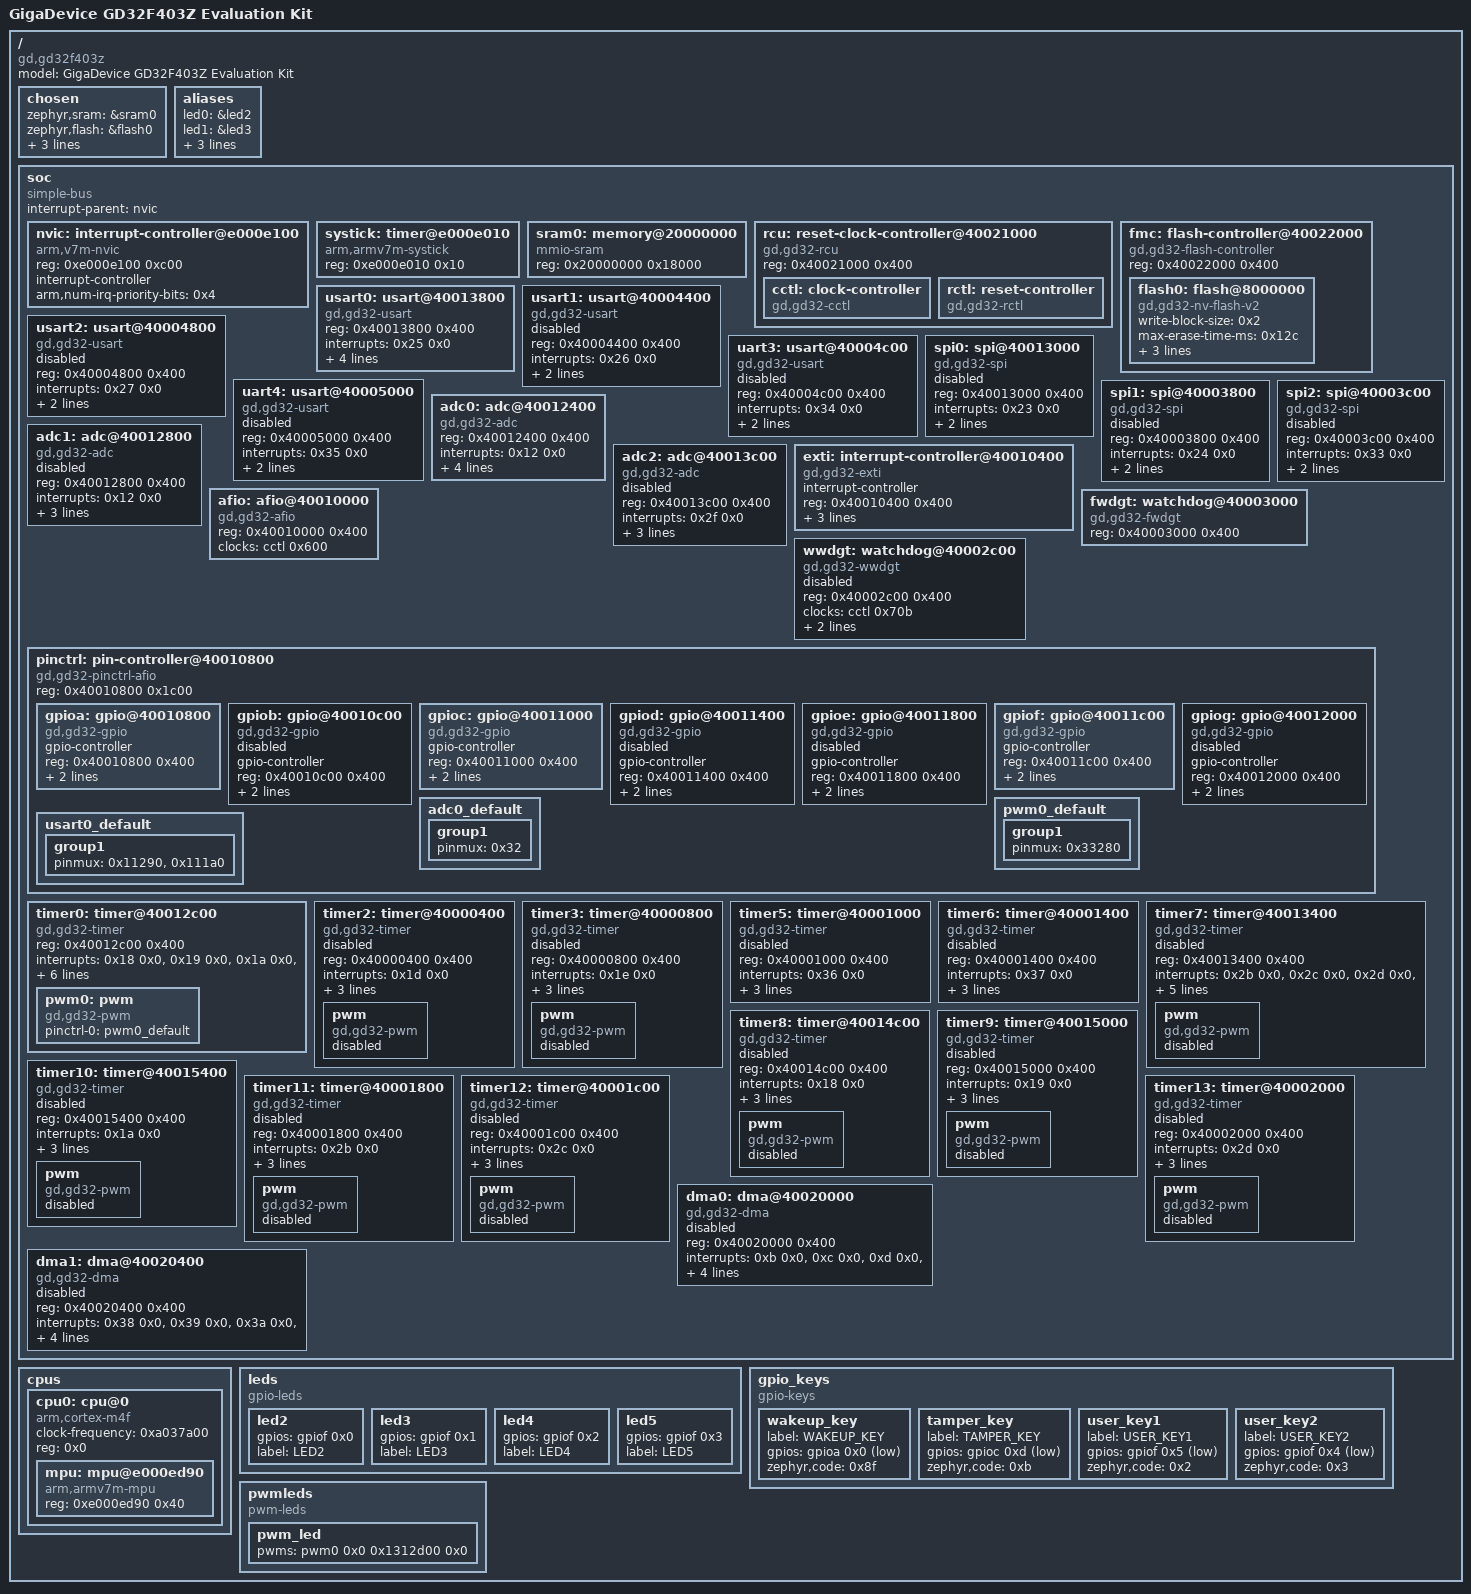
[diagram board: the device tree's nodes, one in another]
/dts-v1/;

/* node '/' defined in zephyr/dts/common/skeleton.dtsi:9 */
/ {
	#address-cells = < 0x1 >;                      /* in zephyr/dts/common/skeleton.dtsi:10 */
	#size-cells = < 0x1 >;                         /* in zephyr/dts/common/skeleton.dtsi:11 */
	model = "GigaDevice GD32F403Z Evaluation Kit"; /* in zephyr/boards/gd/gd32f403z_eval/gd32f403z_eval.dts:13 */
	compatible = "gd,gd32f403z";                   /* in zephyr/boards/gd/gd32f403z_eval/gd32f403z_eval.dts:14 */

	/* node '/chosen' defined in zephyr/dts/common/skeleton.dtsi:13 */
	chosen {
		zephyr,sram = &sram0;           /* in zephyr/boards/gd/gd32f403z_eval/gd32f403z_eval.dts:17 */
		zephyr,flash = &flash0;         /* in zephyr/boards/gd/gd32f403z_eval/gd32f403z_eval.dts:18 */
		zephyr,console = &usart0;       /* in zephyr/boards/gd/gd32f403z_eval/gd32f403z_eval.dts:19 */
		zephyr,shell-uart = &usart0;    /* in zephyr/boards/gd/gd32f403z_eval/gd32f403z_eval.dts:20 */
		zephyr,flash-controller = &fmc; /* in zephyr/boards/gd/gd32f403z_eval/gd32f403z_eval.dts:21 */
	};

	/* node '/aliases' defined in zephyr/dts/common/skeleton.dtsi:15 */
	aliases {
		led0 = &led2;        /* in zephyr/boards/gd/gd32f403z_eval/gd32f403z_eval.dts:86 */
		led1 = &led3;        /* in zephyr/boards/gd/gd32f403z_eval/gd32f403z_eval.dts:87 */
		sw0 = &user_key1;    /* in zephyr/boards/gd/gd32f403z_eval/gd32f403z_eval.dts:88 */
		pwm-led0 = &pwm_led; /* in zephyr/boards/gd/gd32f403z_eval/gd32f403z_eval.dts:89 */
		watchdog0 = &fwdgt;  /* in zephyr/boards/gd/gd32f403z_eval/gd32f403z_eval.dts:90 */
	};

	/* node '/soc' defined in zephyr/dts/arm/armv7-m.dtsi:6 */
	soc {
		#address-cells = < 0x1 >;     /* in zephyr/dts/arm/armv7-m.dtsi:7 */
		#size-cells = < 0x1 >;        /* in zephyr/dts/arm/armv7-m.dtsi:8 */
		compatible = "simple-bus";    /* in zephyr/dts/arm/armv7-m.dtsi:9 */
		interrupt-parent = < &nvic >; /* in zephyr/dts/arm/armv7-m.dtsi:10 */
		ranges;                       /* in zephyr/dts/arm/armv7-m.dtsi:11 */

		/* node '/soc/interrupt-controller@e000e100' defined in zephyr/dts/arm/armv7-m.dtsi:13 */
		nvic: interrupt-controller@e000e100 {
			#address-cells = < 0x1 >;            /* in zephyr/dts/arm/armv7-m.dtsi:14 */
			compatible = "arm,v7m-nvic";         /* in zephyr/dts/arm/armv7-m.dtsi:15 */
			reg = < 0xe000e100 0xc00 >;          /* in zephyr/dts/arm/armv7-m.dtsi:16 */
			interrupt-controller;                /* in zephyr/dts/arm/armv7-m.dtsi:17 */
			#interrupt-cells = < 0x2 >;          /* in zephyr/dts/arm/armv7-m.dtsi:18 */
			arm,num-irq-priority-bits = < 0x4 >; /* in zephyr/dts/arm/gd/gd32f403/gd32f403.dtsi:519 */
			phandle = < 0x1 >;                   /* in zephyr/dts/arm/armv7-m.dtsi:10 */
		};

		/* node '/soc/timer@e000e010' defined in zephyr/dts/arm/armv7-m.dtsi:21 */
		systick: timer@e000e010 {
			compatible = "arm,armv7m-systick"; /* in zephyr/dts/arm/armv7-m.dtsi:22 */
			reg = < 0xe000e010 0x10 >;         /* in zephyr/dts/arm/armv7-m.dtsi:23 */
		};

		/* node '/soc/memory@20000000' defined in zephyr/dts/arm/gd/gd32f403/gd32f403.dtsi:36 */
		sram0: memory@20000000 {
			compatible = "mmio-sram";     /* in zephyr/dts/arm/gd/gd32f403/gd32f403.dtsi:37 */
			reg = < 0x20000000 0x18000 >; /* in zephyr/dts/arm/gd/gd32f403/gd32f403zet6.dtsi:15 */
		};

		/* node '/soc/reset-clock-controller@40021000' defined in zephyr/dts/arm/gd/gd32f403/gd32f403.dtsi:40 */
		rcu: reset-clock-controller@40021000 {
			compatible = "gd,gd32-rcu"; /* in zephyr/dts/arm/gd/gd32f403/gd32f403.dtsi:41 */
			reg = < 0x40021000 0x400 >; /* in zephyr/dts/arm/gd/gd32f403/gd32f403.dtsi:42 */
			status = "okay";            /* in zephyr/dts/arm/gd/gd32f403/gd32f403.dtsi:43 */

			/* node '/soc/reset-clock-controller@40021000/clock-controller' defined in zephyr/dts/arm/gd/gd32f403/gd32f403.dtsi:45 */
			cctl: clock-controller {
				compatible = "gd,gd32-cctl"; /* in zephyr/dts/arm/gd/gd32f403/gd32f403.dtsi:46 */
				#clock-cells = < 0x1 >;      /* in zephyr/dts/arm/gd/gd32f403/gd32f403.dtsi:47 */
				status = "okay";             /* in zephyr/dts/arm/gd/gd32f403/gd32f403.dtsi:48 */
				phandle = < 0x2 >;           /* in zephyr/dts/arm/gd/gd32f403/gd32f403.dtsi:77 */
			};

			/* node '/soc/reset-clock-controller@40021000/reset-controller' defined in zephyr/dts/arm/gd/gd32f403/gd32f403.dtsi:51 */
			rctl: reset-controller {
				compatible = "gd,gd32-rctl"; /* in zephyr/dts/arm/gd/gd32f403/gd32f403.dtsi:52 */
				#reset-cells = < 0x1 >;      /* in zephyr/dts/arm/gd/gd32f403/gd32f403.dtsi:53 */
				status = "okay";             /* in zephyr/dts/arm/gd/gd32f403/gd32f403.dtsi:54 */
				phandle = < 0x3 >;           /* in zephyr/dts/arm/gd/gd32f403/gd32f403.dtsi:78 */
			};
		};

		/* node '/soc/flash-controller@40022000' defined in zephyr/dts/arm/gd/gd32f403/gd32f403.dtsi:58 */
		fmc: flash-controller@40022000 {
			compatible = "gd,gd32-flash-controller"; /* in zephyr/dts/arm/gd/gd32f403/gd32f403.dtsi:59 */
			reg = < 0x40022000 0x400 >;              /* in zephyr/dts/arm/gd/gd32f403/gd32f403.dtsi:60 */
			#address-cells = < 0x1 >;                /* in zephyr/dts/arm/gd/gd32f403/gd32f403.dtsi:61 */
			#size-cells = < 0x1 >;                   /* in zephyr/dts/arm/gd/gd32f403/gd32f403.dtsi:62 */

			/* node '/soc/flash-controller@40022000/flash@8000000' defined in zephyr/dts/arm/gd/gd32f403/gd32f403.dtsi:64 */
			flash0: flash@8000000 {
				compatible = "gd,gd32-nv-flash-v2",
				             "soc-nv-flash";        /* in zephyr/dts/arm/gd/gd32f403/gd32f403.dtsi:65 */
				write-block-size = < 0x2 >;         /* in zephyr/dts/arm/gd/gd32f403/gd32f403.dtsi:66 */
				max-erase-time-ms = < 0x12c >;      /* in zephyr/dts/arm/gd/gd32f403/gd32f403.dtsi:67 */
				bank0-page-size = < 0x800 >;        /* in zephyr/dts/arm/gd/gd32f403/gd32f403.dtsi:68 */
				bank1-page-size = < 0x1000 >;       /* in zephyr/dts/arm/gd/gd32f403/gd32f403.dtsi:69 */
				reg = < 0x8000000 0x80000 >;        /* in zephyr/dts/arm/gd/gd32f403/gd32f403zet6.dtsi:11 */
			};
		};

		/* node '/soc/usart@40013800' defined in zephyr/dts/arm/gd/gd32f403/gd32f403.dtsi:73 */
		usart0: usart@40013800 {
			compatible = "gd,gd32-usart";    /* in zephyr/dts/arm/gd/gd32f403/gd32f403.dtsi:74 */
			reg = < 0x40013800 0x400 >;      /* in zephyr/dts/arm/gd/gd32f403/gd32f403.dtsi:75 */
			interrupts = < 0x25 0x0 >;       /* in zephyr/dts/arm/gd/gd32f403/gd32f403.dtsi:76 */
			clocks = < &cctl 0x60e >;        /* in zephyr/dts/arm/gd/gd32f403/gd32f403.dtsi:77 */
			resets = < &rctl 0x30e >;        /* in zephyr/dts/arm/gd/gd32f403/gd32f403.dtsi:78 */
			status = "okay";                 /* in zephyr/boards/gd/gd32f403z_eval/gd32f403z_eval.dts:113 */
			current-speed = < 0x1c200 >;     /* in zephyr/boards/gd/gd32f403z_eval/gd32f403z_eval.dts:114 */
			pinctrl-0 = < &usart0_default >; /* in zephyr/boards/gd/gd32f403z_eval/gd32f403z_eval.dts:115 */
			pinctrl-names = "default";       /* in zephyr/boards/gd/gd32f403z_eval/gd32f403z_eval.dts:116 */
		};

		/* node '/soc/usart@40004400' defined in zephyr/dts/arm/gd/gd32f403/gd32f403.dtsi:82 */
		usart1: usart@40004400 {
			compatible = "gd,gd32-usart"; /* in zephyr/dts/arm/gd/gd32f403/gd32f403.dtsi:83 */
			reg = < 0x40004400 0x400 >;   /* in zephyr/dts/arm/gd/gd32f403/gd32f403.dtsi:84 */
			interrupts = < 0x26 0x0 >;    /* in zephyr/dts/arm/gd/gd32f403/gd32f403.dtsi:85 */
			clocks = < &cctl 0x711 >;     /* in zephyr/dts/arm/gd/gd32f403/gd32f403.dtsi:86 */
			resets = < &rctl 0x411 >;     /* in zephyr/dts/arm/gd/gd32f403/gd32f403.dtsi:87 */
			status = "disabled";          /* in zephyr/dts/arm/gd/gd32f403/gd32f403.dtsi:88 */
		};

		/* node '/soc/usart@40004800' defined in zephyr/dts/arm/gd/gd32f403/gd32f403.dtsi:91 */
		usart2: usart@40004800 {
			compatible = "gd,gd32-usart"; /* in zephyr/dts/arm/gd/gd32f403/gd32f403.dtsi:92 */
			reg = < 0x40004800 0x400 >;   /* in zephyr/dts/arm/gd/gd32f403/gd32f403.dtsi:93 */
			interrupts = < 0x27 0x0 >;    /* in zephyr/dts/arm/gd/gd32f403/gd32f403.dtsi:94 */
			clocks = < &cctl 0x712 >;     /* in zephyr/dts/arm/gd/gd32f403/gd32f403.dtsi:95 */
			resets = < &rctl 0x412 >;     /* in zephyr/dts/arm/gd/gd32f403/gd32f403.dtsi:96 */
			status = "disabled";          /* in zephyr/dts/arm/gd/gd32f403/gd32f403.dtsi:97 */
		};

		/* node '/soc/usart@40004c00' defined in zephyr/dts/arm/gd/gd32f403/gd32f403.dtsi:100 */
		uart3: usart@40004c00 {
			compatible = "gd,gd32-usart"; /* in zephyr/dts/arm/gd/gd32f403/gd32f403.dtsi:101 */
			reg = < 0x40004c00 0x400 >;   /* in zephyr/dts/arm/gd/gd32f403/gd32f403.dtsi:102 */
			interrupts = < 0x34 0x0 >;    /* in zephyr/dts/arm/gd/gd32f403/gd32f403.dtsi:103 */
			clocks = < &cctl 0x713 >;     /* in zephyr/dts/arm/gd/gd32f403/gd32f403.dtsi:104 */
			resets = < &rctl 0x413 >;     /* in zephyr/dts/arm/gd/gd32f403/gd32f403.dtsi:105 */
			status = "disabled";          /* in zephyr/dts/arm/gd/gd32f403/gd32f403.dtsi:106 */
		};

		/* node '/soc/usart@40005000' defined in zephyr/dts/arm/gd/gd32f403/gd32f403.dtsi:109 */
		uart4: usart@40005000 {
			compatible = "gd,gd32-usart"; /* in zephyr/dts/arm/gd/gd32f403/gd32f403.dtsi:110 */
			reg = < 0x40005000 0x400 >;   /* in zephyr/dts/arm/gd/gd32f403/gd32f403.dtsi:111 */
			interrupts = < 0x35 0x0 >;    /* in zephyr/dts/arm/gd/gd32f403/gd32f403.dtsi:112 */
			clocks = < &cctl 0x714 >;     /* in zephyr/dts/arm/gd/gd32f403/gd32f403.dtsi:113 */
			resets = < &rctl 0x414 >;     /* in zephyr/dts/arm/gd/gd32f403/gd32f403.dtsi:114 */
			status = "disabled";          /* in zephyr/dts/arm/gd/gd32f403/gd32f403.dtsi:115 */
		};

		/* node '/soc/spi@40013000' defined in zephyr/dts/arm/gd/gd32f403/gd32f403.dtsi:118 */
		spi0: spi@40013000 {
			compatible = "gd,gd32-spi"; /* in zephyr/dts/arm/gd/gd32f403/gd32f403.dtsi:119 */
			reg = < 0x40013000 0x400 >; /* in zephyr/dts/arm/gd/gd32f403/gd32f403.dtsi:120 */
			interrupts = < 0x23 0x0 >;  /* in zephyr/dts/arm/gd/gd32f403/gd32f403.dtsi:121 */
			clocks = < &cctl 0x60c >;   /* in zephyr/dts/arm/gd/gd32f403/gd32f403.dtsi:122 */
			resets = < &rctl 0x30c >;   /* in zephyr/dts/arm/gd/gd32f403/gd32f403.dtsi:123 */
			status = "disabled";        /* in zephyr/dts/arm/gd/gd32f403/gd32f403.dtsi:124 */
			#address-cells = < 0x1 >;   /* in zephyr/dts/arm/gd/gd32f403/gd32f403.dtsi:125 */
			#size-cells = < 0x0 >;      /* in zephyr/dts/arm/gd/gd32f403/gd32f403.dtsi:126 */
		};

		/* node '/soc/spi@40003800' defined in zephyr/dts/arm/gd/gd32f403/gd32f403.dtsi:129 */
		spi1: spi@40003800 {
			compatible = "gd,gd32-spi"; /* in zephyr/dts/arm/gd/gd32f403/gd32f403.dtsi:130 */
			reg = < 0x40003800 0x400 >; /* in zephyr/dts/arm/gd/gd32f403/gd32f403.dtsi:131 */
			interrupts = < 0x24 0x0 >;  /* in zephyr/dts/arm/gd/gd32f403/gd32f403.dtsi:132 */
			clocks = < &cctl 0x70e >;   /* in zephyr/dts/arm/gd/gd32f403/gd32f403.dtsi:133 */
			resets = < &rctl 0x40e >;   /* in zephyr/dts/arm/gd/gd32f403/gd32f403.dtsi:134 */
			status = "disabled";        /* in zephyr/dts/arm/gd/gd32f403/gd32f403.dtsi:135 */
			#address-cells = < 0x1 >;   /* in zephyr/dts/arm/gd/gd32f403/gd32f403.dtsi:136 */
			#size-cells = < 0x0 >;      /* in zephyr/dts/arm/gd/gd32f403/gd32f403.dtsi:137 */
		};

		/* node '/soc/spi@40003c00' defined in zephyr/dts/arm/gd/gd32f403/gd32f403.dtsi:140 */
		spi2: spi@40003c00 {
			compatible = "gd,gd32-spi"; /* in zephyr/dts/arm/gd/gd32f403/gd32f403.dtsi:141 */
			reg = < 0x40003c00 0x400 >; /* in zephyr/dts/arm/gd/gd32f403/gd32f403.dtsi:142 */
			interrupts = < 0x33 0x0 >;  /* in zephyr/dts/arm/gd/gd32f403/gd32f403.dtsi:143 */
			clocks = < &cctl 0x70f >;   /* in zephyr/dts/arm/gd/gd32f403/gd32f403.dtsi:144 */
			resets = < &rctl 0x40f >;   /* in zephyr/dts/arm/gd/gd32f403/gd32f403.dtsi:145 */
			status = "disabled";        /* in zephyr/dts/arm/gd/gd32f403/gd32f403.dtsi:146 */
			#address-cells = < 0x1 >;   /* in zephyr/dts/arm/gd/gd32f403/gd32f403.dtsi:147 */
			#size-cells = < 0x0 >;      /* in zephyr/dts/arm/gd/gd32f403/gd32f403.dtsi:148 */
		};

		/* node '/soc/adc@40012400' defined in zephyr/dts/arm/gd/gd32f403/gd32f403.dtsi:151 */
		adc0: adc@40012400 {
			compatible = "gd,gd32-adc";    /* in zephyr/dts/arm/gd/gd32f403/gd32f403.dtsi:152 */
			reg = < 0x40012400 0x400 >;    /* in zephyr/dts/arm/gd/gd32f403/gd32f403.dtsi:153 */
			interrupts = < 0x12 0x0 >;     /* in zephyr/dts/arm/gd/gd32f403/gd32f403.dtsi:154 */
			clocks = < &cctl 0x609 >;      /* in zephyr/dts/arm/gd/gd32f403/gd32f403.dtsi:155 */
			resets = < &rctl 0x309 >;      /* in zephyr/dts/arm/gd/gd32f403/gd32f403.dtsi:156 */
			channels = < 0x10 >;           /* in zephyr/dts/arm/gd/gd32f403/gd32f403.dtsi:157 */
			#io-channel-cells = < 0x1 >;   /* in zephyr/dts/arm/gd/gd32f403/gd32f403.dtsi:159 */
			status = "okay";               /* in zephyr/boards/gd/gd32f403z_eval/gd32f403z_eval.dts:107 */
			pinctrl-0 = < &adc0_default >; /* in zephyr/boards/gd/gd32f403z_eval/gd32f403z_eval.dts:108 */
			pinctrl-names = "default";     /* in zephyr/boards/gd/gd32f403z_eval/gd32f403z_eval.dts:109 */
		};

		/* node '/soc/adc@40012800' defined in zephyr/dts/arm/gd/gd32f403/gd32f403.dtsi:162 */
		adc1: adc@40012800 {
			compatible = "gd,gd32-adc";  /* in zephyr/dts/arm/gd/gd32f403/gd32f403.dtsi:163 */
			reg = < 0x40012800 0x400 >;  /* in zephyr/dts/arm/gd/gd32f403/gd32f403.dtsi:164 */
			interrupts = < 0x12 0x0 >;   /* in zephyr/dts/arm/gd/gd32f403/gd32f403.dtsi:165 */
			clocks = < &cctl 0x60a >;    /* in zephyr/dts/arm/gd/gd32f403/gd32f403.dtsi:166 */
			resets = < &rctl 0x30a >;    /* in zephyr/dts/arm/gd/gd32f403/gd32f403.dtsi:167 */
			channels = < 0x10 >;         /* in zephyr/dts/arm/gd/gd32f403/gd32f403.dtsi:168 */
			status = "disabled";         /* in zephyr/dts/arm/gd/gd32f403/gd32f403.dtsi:169 */
			#io-channel-cells = < 0x1 >; /* in zephyr/dts/arm/gd/gd32f403/gd32f403.dtsi:170 */
		};

		/* node '/soc/adc@40013c00' defined in zephyr/dts/arm/gd/gd32f403/gd32f403.dtsi:173 */
		adc2: adc@40013c00 {
			compatible = "gd,gd32-adc";  /* in zephyr/dts/arm/gd/gd32f403/gd32f403.dtsi:174 */
			reg = < 0x40013c00 0x400 >;  /* in zephyr/dts/arm/gd/gd32f403/gd32f403.dtsi:175 */
			interrupts = < 0x2f 0x0 >;   /* in zephyr/dts/arm/gd/gd32f403/gd32f403.dtsi:176 */
			clocks = < &cctl 0x60f >;    /* in zephyr/dts/arm/gd/gd32f403/gd32f403.dtsi:177 */
			resets = < &rctl 0x30f >;    /* in zephyr/dts/arm/gd/gd32f403/gd32f403.dtsi:178 */
			channels = < 0x10 >;         /* in zephyr/dts/arm/gd/gd32f403/gd32f403.dtsi:179 */
			status = "disabled";         /* in zephyr/dts/arm/gd/gd32f403/gd32f403.dtsi:180 */
			#io-channel-cells = < 0x1 >; /* in zephyr/dts/arm/gd/gd32f403/gd32f403.dtsi:181 */
		};

		/* node '/soc/interrupt-controller@40010400' defined in zephyr/dts/arm/gd/gd32f403/gd32f403.dtsi:184 */
		exti: interrupt-controller@40010400 {
			compatible = "gd,gd32-exti";   /* in zephyr/dts/arm/gd/gd32f403/gd32f403.dtsi:185 */
			interrupt-controller;          /* in zephyr/dts/arm/gd/gd32f403/gd32f403.dtsi:186 */
			#interrupt-cells = < 0x1 >;    /* in zephyr/dts/arm/gd/gd32f403/gd32f403.dtsi:187 */
			reg = < 0x40010400 0x400 >;    /* in zephyr/dts/arm/gd/gd32f403/gd32f403.dtsi:188 */
			num-lines = < 0x13 >;          /* in zephyr/dts/arm/gd/gd32f403/gd32f403.dtsi:189 */
			interrupts = < 0x6 0x0 >,
			             < 0x7 0x0 >,
			             < 0x8 0x0 >,
			             < 0x9 0x0 >,
			             < 0xa 0x0 >,
			             < 0x17 0x0 >,
			             < 0x28 0x0 >;     /* in zephyr/dts/arm/gd/gd32f403/gd32f403.dtsi:190 */
			interrupt-names = "line0",
			                  "line1",
			                  "line2",
			                  "line3",
			                  "line4",
			                  "line5-9",
			                  "line10-15"; /* in zephyr/dts/arm/gd/gd32f403/gd32f403.dtsi:192 */
			status = "okay";               /* in zephyr/dts/arm/gd/gd32f403/gd32f403.dtsi:195 */
		};

		/* node '/soc/afio@40010000' defined in zephyr/dts/arm/gd/gd32f403/gd32f403.dtsi:198 */
		afio: afio@40010000 {
			compatible = "gd,gd32-afio"; /* in zephyr/dts/arm/gd/gd32f403/gd32f403.dtsi:199 */
			reg = < 0x40010000 0x400 >;  /* in zephyr/dts/arm/gd/gd32f403/gd32f403.dtsi:200 */
			clocks = < &cctl 0x600 >;    /* in zephyr/dts/arm/gd/gd32f403/gd32f403.dtsi:201 */
			status = "okay";             /* in zephyr/dts/arm/gd/gd32f403/gd32f403.dtsi:202 */
		};

		/* node '/soc/watchdog@40003000' defined in zephyr/dts/arm/gd/gd32f403/gd32f403.dtsi:205 */
		fwdgt: watchdog@40003000 {
			compatible = "gd,gd32-fwdgt"; /* in zephyr/dts/arm/gd/gd32f403/gd32f403.dtsi:206 */
			reg = < 0x40003000 0x400 >;   /* in zephyr/dts/arm/gd/gd32f403/gd32f403.dtsi:207 */
			status = "okay";              /* in zephyr/boards/gd/gd32f403z_eval/gd32f403z_eval.dts:131 */
		};

		/* node '/soc/watchdog@40002c00' defined in zephyr/dts/arm/gd/gd32f403/gd32f403.dtsi:211 */
		wwdgt: watchdog@40002c00 {
			compatible = "gd,gd32-wwdgt"; /* in zephyr/dts/arm/gd/gd32f403/gd32f403.dtsi:212 */
			reg = < 0x40002c00 0x400 >;   /* in zephyr/dts/arm/gd/gd32f403/gd32f403.dtsi:213 */
			clocks = < &cctl 0x70b >;     /* in zephyr/dts/arm/gd/gd32f403/gd32f403.dtsi:214 */
			resets = < &rctl 0x40b >;     /* in zephyr/dts/arm/gd/gd32f403/gd32f403.dtsi:215 */
			interrupts = < 0x0 0x0 >;     /* in zephyr/dts/arm/gd/gd32f403/gd32f403.dtsi:216 */
			status = "disabled";          /* in zephyr/dts/arm/gd/gd32f403/gd32f403.dtsi:217 */
		};

		/* node '/soc/pin-controller@40010800' defined in zephyr/dts/arm/gd/gd32f403/gd32f403.dtsi:220 */
		pinctrl: pin-controller@40010800 {
			compatible = "gd,gd32-pinctrl-afio"; /* in zephyr/dts/arm/gd/gd32f403/gd32f403.dtsi:221 */
			reg = < 0x40010800 0x1c00 >;         /* in zephyr/dts/arm/gd/gd32f403/gd32f403.dtsi:222 */
			#address-cells = < 0x1 >;            /* in zephyr/dts/arm/gd/gd32f403/gd32f403.dtsi:223 */
			#size-cells = < 0x1 >;               /* in zephyr/dts/arm/gd/gd32f403/gd32f403.dtsi:224 */
			status = "okay";                     /* in zephyr/dts/arm/gd/gd32f403/gd32f403.dtsi:225 */

			/* node '/soc/pin-controller@40010800/gpio@40010800' defined in zephyr/dts/arm/gd/gd32f403/gd32f403.dtsi:227 */
			gpioa: gpio@40010800 {
				compatible = "gd,gd32-gpio"; /* in zephyr/dts/arm/gd/gd32f403/gd32f403.dtsi:228 */
				gpio-controller;             /* in zephyr/dts/arm/gd/gd32f403/gd32f403.dtsi:229 */
				#gpio-cells = < 0x2 >;       /* in zephyr/dts/arm/gd/gd32f403/gd32f403.dtsi:230 */
				reg = < 0x40010800 0x400 >;  /* in zephyr/dts/arm/gd/gd32f403/gd32f403.dtsi:231 */
				clocks = < &cctl 0x602 >;    /* in zephyr/dts/arm/gd/gd32f403/gd32f403.dtsi:232 */
				resets = < &rctl 0x302 >;    /* in zephyr/dts/arm/gd/gd32f403/gd32f403.dtsi:233 */
				status = "okay";             /* in zephyr/boards/gd/gd32f403z_eval/gd32f403z_eval.dts:95 */
				phandle = < 0x8 >;           /* in zephyr/boards/gd/gd32f403z_eval/gd32f403z_eval.dts:53 */
			};

			/* node '/soc/pin-controller@40010800/gpio@40010c00' defined in zephyr/dts/arm/gd/gd32f403/gd32f403.dtsi:237 */
			gpiob: gpio@40010c00 {
				compatible = "gd,gd32-gpio"; /* in zephyr/dts/arm/gd/gd32f403/gd32f403.dtsi:238 */
				gpio-controller;             /* in zephyr/dts/arm/gd/gd32f403/gd32f403.dtsi:239 */
				#gpio-cells = < 0x2 >;       /* in zephyr/dts/arm/gd/gd32f403/gd32f403.dtsi:240 */
				reg = < 0x40010c00 0x400 >;  /* in zephyr/dts/arm/gd/gd32f403/gd32f403.dtsi:241 */
				clocks = < &cctl 0x603 >;    /* in zephyr/dts/arm/gd/gd32f403/gd32f403.dtsi:242 */
				resets = < &rctl 0x303 >;    /* in zephyr/dts/arm/gd/gd32f403/gd32f403.dtsi:243 */
				status = "disabled";         /* in zephyr/dts/arm/gd/gd32f403/gd32f403.dtsi:244 */
			};

			/* node '/soc/pin-controller@40010800/gpio@40011000' defined in zephyr/dts/arm/gd/gd32f403/gd32f403.dtsi:247 */
			gpioc: gpio@40011000 {
				compatible = "gd,gd32-gpio"; /* in zephyr/dts/arm/gd/gd32f403/gd32f403.dtsi:248 */
				gpio-controller;             /* in zephyr/dts/arm/gd/gd32f403/gd32f403.dtsi:249 */
				#gpio-cells = < 0x2 >;       /* in zephyr/dts/arm/gd/gd32f403/gd32f403.dtsi:250 */
				reg = < 0x40011000 0x400 >;  /* in zephyr/dts/arm/gd/gd32f403/gd32f403.dtsi:251 */
				clocks = < &cctl 0x604 >;    /* in zephyr/dts/arm/gd/gd32f403/gd32f403.dtsi:252 */
				resets = < &rctl 0x304 >;    /* in zephyr/dts/arm/gd/gd32f403/gd32f403.dtsi:253 */
				status = "okay";             /* in zephyr/boards/gd/gd32f403z_eval/gd32f403z_eval.dts:99 */
				phandle = < 0x9 >;           /* in zephyr/boards/gd/gd32f403z_eval/gd32f403z_eval.dts:59 */
			};

			/* node '/soc/pin-controller@40010800/gpio@40011400' defined in zephyr/dts/arm/gd/gd32f403/gd32f403.dtsi:257 */
			gpiod: gpio@40011400 {
				compatible = "gd,gd32-gpio"; /* in zephyr/dts/arm/gd/gd32f403/gd32f403.dtsi:258 */
				gpio-controller;             /* in zephyr/dts/arm/gd/gd32f403/gd32f403.dtsi:259 */
				#gpio-cells = < 0x2 >;       /* in zephyr/dts/arm/gd/gd32f403/gd32f403.dtsi:260 */
				reg = < 0x40011400 0x400 >;  /* in zephyr/dts/arm/gd/gd32f403/gd32f403.dtsi:261 */
				clocks = < &cctl 0x605 >;    /* in zephyr/dts/arm/gd/gd32f403/gd32f403.dtsi:262 */
				resets = < &rctl 0x305 >;    /* in zephyr/dts/arm/gd/gd32f403/gd32f403.dtsi:263 */
				status = "disabled";         /* in zephyr/dts/arm/gd/gd32f403/gd32f403.dtsi:264 */
			};

			/* node '/soc/pin-controller@40010800/gpio@40011800' defined in zephyr/dts/arm/gd/gd32f403/gd32f403.dtsi:267 */
			gpioe: gpio@40011800 {
				compatible = "gd,gd32-gpio"; /* in zephyr/dts/arm/gd/gd32f403/gd32f403.dtsi:268 */
				gpio-controller;             /* in zephyr/dts/arm/gd/gd32f403/gd32f403.dtsi:269 */
				#gpio-cells = < 0x2 >;       /* in zephyr/dts/arm/gd/gd32f403/gd32f403.dtsi:270 */
				reg = < 0x40011800 0x400 >;  /* in zephyr/dts/arm/gd/gd32f403/gd32f403.dtsi:271 */
				clocks = < &cctl 0x606 >;    /* in zephyr/dts/arm/gd/gd32f403/gd32f403.dtsi:272 */
				resets = < &rctl 0x306 >;    /* in zephyr/dts/arm/gd/gd32f403/gd32f403.dtsi:273 */
				status = "disabled";         /* in zephyr/dts/arm/gd/gd32f403/gd32f403.dtsi:274 */
			};

			/* node '/soc/pin-controller@40010800/gpio@40011c00' defined in zephyr/dts/arm/gd/gd32f403/gd32f403.dtsi:277 */
			gpiof: gpio@40011c00 {
				compatible = "gd,gd32-gpio"; /* in zephyr/dts/arm/gd/gd32f403/gd32f403.dtsi:278 */
				gpio-controller;             /* in zephyr/dts/arm/gd/gd32f403/gd32f403.dtsi:279 */
				#gpio-cells = < 0x2 >;       /* in zephyr/dts/arm/gd/gd32f403/gd32f403.dtsi:280 */
				reg = < 0x40011c00 0x400 >;  /* in zephyr/dts/arm/gd/gd32f403/gd32f403.dtsi:281 */
				clocks = < &cctl 0x607 >;    /* in zephyr/dts/arm/gd/gd32f403/gd32f403.dtsi:282 */
				resets = < &rctl 0x307 >;    /* in zephyr/dts/arm/gd/gd32f403/gd32f403.dtsi:283 */
				status = "okay";             /* in zephyr/boards/gd/gd32f403z_eval/gd32f403z_eval.dts:103 */
				phandle = < 0x7 >;           /* in zephyr/boards/gd/gd32f403z_eval/gd32f403z_eval.dts:28 */
			};

			/* node '/soc/pin-controller@40010800/gpio@40012000' defined in zephyr/dts/arm/gd/gd32f403/gd32f403.dtsi:287 */
			gpiog: gpio@40012000 {
				compatible = "gd,gd32-gpio"; /* in zephyr/dts/arm/gd/gd32f403/gd32f403.dtsi:288 */
				gpio-controller;             /* in zephyr/dts/arm/gd/gd32f403/gd32f403.dtsi:289 */
				#gpio-cells = < 0x2 >;       /* in zephyr/dts/arm/gd/gd32f403/gd32f403.dtsi:290 */
				reg = < 0x40012000 0x400 >;  /* in zephyr/dts/arm/gd/gd32f403/gd32f403.dtsi:291 */
				clocks = < &cctl 0x608 >;    /* in zephyr/dts/arm/gd/gd32f403/gd32f403.dtsi:292 */
				resets = < &rctl 0x308 >;    /* in zephyr/dts/arm/gd/gd32f403/gd32f403.dtsi:293 */
				status = "disabled";         /* in zephyr/dts/arm/gd/gd32f403/gd32f403.dtsi:294 */
			};

			/* node '/soc/pin-controller@40010800/usart0_default' defined in zephyr/boards/gd/gd32f403z_eval/gd32f403z_eval-pinctrl.dtsi:9 */
			usart0_default: usart0_default {
				phandle = < 0x4 >; /* in zephyr/boards/gd/gd32f403z_eval/gd32f403z_eval.dts:115 */

				/* node '/soc/pin-controller@40010800/usart0_default/group1' defined in zephyr/boards/gd/gd32f403z_eval/gd32f403z_eval-pinctrl.dtsi:10 */
				group1 {
					pinmux = < 0x11290 >,
					         < 0x111a0 >; /* in zephyr/boards/gd/gd32f403z_eval/gd32f403z_eval-pinctrl.dtsi:11 */
				};
			};

			/* node '/soc/pin-controller@40010800/adc0_default' defined in zephyr/boards/gd/gd32f403z_eval/gd32f403z_eval-pinctrl.dtsi:15 */
			adc0_default: adc0_default {
				phandle = < 0x5 >; /* in zephyr/boards/gd/gd32f403z_eval/gd32f403z_eval.dts:108 */

				/* node '/soc/pin-controller@40010800/adc0_default/group1' defined in zephyr/boards/gd/gd32f403z_eval/gd32f403z_eval-pinctrl.dtsi:16 */
				group1 {
					pinmux = < 0x32 >; /* in zephyr/boards/gd/gd32f403z_eval/gd32f403z_eval-pinctrl.dtsi:17 */
				};
			};

			/* node '/soc/pin-controller@40010800/pwm0_default' defined in zephyr/boards/gd/gd32f403z_eval/gd32f403z_eval-pinctrl.dtsi:21 */
			pwm0_default: pwm0_default {
				phandle = < 0x6 >; /* in zephyr/boards/gd/gd32f403z_eval/gd32f403z_eval.dts:125 */

				/* node '/soc/pin-controller@40010800/pwm0_default/group1' defined in zephyr/boards/gd/gd32f403z_eval/gd32f403z_eval-pinctrl.dtsi:22 */
				group1 {
					pinmux = < 0x33280 >; /* in zephyr/boards/gd/gd32f403z_eval/gd32f403z_eval-pinctrl.dtsi:23 */
				};
			};
		};

		/* node '/soc/timer@40012c00' defined in zephyr/dts/arm/gd/gd32f403/gd32f403.dtsi:298 */
		timer0: timer@40012c00 {
			compatible = "gd,gd32-timer"; /* in zephyr/dts/arm/gd/gd32f403/gd32f403.dtsi:299 */
			reg = < 0x40012c00 0x400 >;   /* in zephyr/dts/arm/gd/gd32f403/gd32f403.dtsi:300 */
			interrupts = < 0x18 0x0 >,
			             < 0x19 0x0 >,
			             < 0x1a 0x0 >,
			             < 0x1b 0x0 >;    /* in zephyr/dts/arm/gd/gd32f403/gd32f403.dtsi:301 */
			interrupt-names = "brk",
			                  "up",
			                  "trgcom",
			                  "cc";       /* in zephyr/dts/arm/gd/gd32f403/gd32f403.dtsi:302 */
			clocks = < &cctl 0x60b >;     /* in zephyr/dts/arm/gd/gd32f403/gd32f403.dtsi:303 */
			resets = < &rctl 0x30b >;     /* in zephyr/dts/arm/gd/gd32f403/gd32f403.dtsi:304 */
			is-advanced;                  /* in zephyr/dts/arm/gd/gd32f403/gd32f403.dtsi:305 */
			channels = < 0x4 >;           /* in zephyr/dts/arm/gd/gd32f403/gd32f403.dtsi:306 */
			status = "okay";              /* in zephyr/boards/gd/gd32f403z_eval/gd32f403z_eval.dts:120 */
			prescaler = < 0x100 >;        /* in zephyr/boards/gd/gd32f403z_eval/gd32f403z_eval.dts:121 */

			/* node '/soc/timer@40012c00/pwm' defined in zephyr/dts/arm/gd/gd32f403/gd32f403.dtsi:309 */
			pwm0: pwm {
				compatible = "gd,gd32-pwm";    /* in zephyr/dts/arm/gd/gd32f403/gd32f403.dtsi:310 */
				#pwm-cells = < 0x3 >;          /* in zephyr/dts/arm/gd/gd32f403/gd32f403.dtsi:312 */
				status = "okay";               /* in zephyr/boards/gd/gd32f403z_eval/gd32f403z_eval.dts:124 */
				pinctrl-0 = < &pwm0_default >; /* in zephyr/boards/gd/gd32f403z_eval/gd32f403z_eval.dts:125 */
				pinctrl-names = "default";     /* in zephyr/boards/gd/gd32f403z_eval/gd32f403z_eval.dts:126 */
				phandle = < 0xa >;             /* in zephyr/boards/gd/gd32f403z_eval/gd32f403z_eval.dts:81 */
			};
		};

		/* node '/soc/timer@40000400' defined in zephyr/dts/arm/gd/gd32f403/gd32f403.dtsi:316 */
		timer2: timer@40000400 {
			compatible = "gd,gd32-timer"; /* in zephyr/dts/arm/gd/gd32f403/gd32f403.dtsi:317 */
			reg = < 0x40000400 0x400 >;   /* in zephyr/dts/arm/gd/gd32f403/gd32f403.dtsi:318 */
			interrupts = < 0x1d 0x0 >;    /* in zephyr/dts/arm/gd/gd32f403/gd32f403.dtsi:319 */
			interrupt-names = "global";   /* in zephyr/dts/arm/gd/gd32f403/gd32f403.dtsi:320 */
			clocks = < &cctl 0x701 >;     /* in zephyr/dts/arm/gd/gd32f403/gd32f403.dtsi:321 */
			resets = < &rctl 0x401 >;     /* in zephyr/dts/arm/gd/gd32f403/gd32f403.dtsi:322 */
			channels = < 0x4 >;           /* in zephyr/dts/arm/gd/gd32f403/gd32f403.dtsi:323 */
			status = "disabled";          /* in zephyr/dts/arm/gd/gd32f403/gd32f403.dtsi:324 */

			/* node '/soc/timer@40000400/pwm' defined in zephyr/dts/arm/gd/gd32f403/gd32f403.dtsi:326 */
			pwm {
				compatible = "gd,gd32-pwm"; /* in zephyr/dts/arm/gd/gd32f403/gd32f403.dtsi:327 */
				status = "disabled";        /* in zephyr/dts/arm/gd/gd32f403/gd32f403.dtsi:328 */
				#pwm-cells = < 0x3 >;       /* in zephyr/dts/arm/gd/gd32f403/gd32f403.dtsi:329 */
			};
		};

		/* node '/soc/timer@40000800' defined in zephyr/dts/arm/gd/gd32f403/gd32f403.dtsi:333 */
		timer3: timer@40000800 {
			compatible = "gd,gd32-timer"; /* in zephyr/dts/arm/gd/gd32f403/gd32f403.dtsi:334 */
			reg = < 0x40000800 0x400 >;   /* in zephyr/dts/arm/gd/gd32f403/gd32f403.dtsi:335 */
			interrupts = < 0x1e 0x0 >;    /* in zephyr/dts/arm/gd/gd32f403/gd32f403.dtsi:336 */
			interrupt-names = "global";   /* in zephyr/dts/arm/gd/gd32f403/gd32f403.dtsi:337 */
			clocks = < &cctl 0x702 >;     /* in zephyr/dts/arm/gd/gd32f403/gd32f403.dtsi:338 */
			resets = < &rctl 0x402 >;     /* in zephyr/dts/arm/gd/gd32f403/gd32f403.dtsi:339 */
			channels = < 0x4 >;           /* in zephyr/dts/arm/gd/gd32f403/gd32f403.dtsi:340 */
			status = "disabled";          /* in zephyr/dts/arm/gd/gd32f403/gd32f403.dtsi:341 */

			/* node '/soc/timer@40000800/pwm' defined in zephyr/dts/arm/gd/gd32f403/gd32f403.dtsi:343 */
			pwm {
				compatible = "gd,gd32-pwm"; /* in zephyr/dts/arm/gd/gd32f403/gd32f403.dtsi:344 */
				status = "disabled";        /* in zephyr/dts/arm/gd/gd32f403/gd32f403.dtsi:345 */
				#pwm-cells = < 0x3 >;       /* in zephyr/dts/arm/gd/gd32f403/gd32f403.dtsi:346 */
			};
		};

		/* node '/soc/timer@40001000' defined in zephyr/dts/arm/gd/gd32f403/gd32f403.dtsi:350 */
		timer5: timer@40001000 {
			compatible = "gd,gd32-timer"; /* in zephyr/dts/arm/gd/gd32f403/gd32f403.dtsi:351 */
			reg = < 0x40001000 0x400 >;   /* in zephyr/dts/arm/gd/gd32f403/gd32f403.dtsi:352 */
			interrupts = < 0x36 0x0 >;    /* in zephyr/dts/arm/gd/gd32f403/gd32f403.dtsi:353 */
			interrupt-names = "global";   /* in zephyr/dts/arm/gd/gd32f403/gd32f403.dtsi:354 */
			clocks = < &cctl 0x704 >;     /* in zephyr/dts/arm/gd/gd32f403/gd32f403.dtsi:355 */
			resets = < &rctl 0x404 >;     /* in zephyr/dts/arm/gd/gd32f403/gd32f403.dtsi:356 */
			channels = < 0x0 >;           /* in zephyr/dts/arm/gd/gd32f403/gd32f403.dtsi:357 */
			status = "disabled";          /* in zephyr/dts/arm/gd/gd32f403/gd32f403.dtsi:358 */
		};

		/* node '/soc/timer@40001400' defined in zephyr/dts/arm/gd/gd32f403/gd32f403.dtsi:361 */
		timer6: timer@40001400 {
			compatible = "gd,gd32-timer"; /* in zephyr/dts/arm/gd/gd32f403/gd32f403.dtsi:362 */
			reg = < 0x40001400 0x400 >;   /* in zephyr/dts/arm/gd/gd32f403/gd32f403.dtsi:363 */
			interrupts = < 0x37 0x0 >;    /* in zephyr/dts/arm/gd/gd32f403/gd32f403.dtsi:364 */
			interrupt-names = "global";   /* in zephyr/dts/arm/gd/gd32f403/gd32f403.dtsi:365 */
			clocks = < &cctl 0x705 >;     /* in zephyr/dts/arm/gd/gd32f403/gd32f403.dtsi:366 */
			resets = < &rctl 0x405 >;     /* in zephyr/dts/arm/gd/gd32f403/gd32f403.dtsi:367 */
			channels = < 0x0 >;           /* in zephyr/dts/arm/gd/gd32f403/gd32f403.dtsi:368 */
			status = "disabled";          /* in zephyr/dts/arm/gd/gd32f403/gd32f403.dtsi:369 */
		};

		/* node '/soc/timer@40013400' defined in zephyr/dts/arm/gd/gd32f403/gd32f403.dtsi:372 */
		timer7: timer@40013400 {
			compatible = "gd,gd32-timer"; /* in zephyr/dts/arm/gd/gd32f403/gd32f403.dtsi:373 */
			reg = < 0x40013400 0x400 >;   /* in zephyr/dts/arm/gd/gd32f403/gd32f403.dtsi:374 */
			interrupts = < 0x2b 0x0 >,
			             < 0x2c 0x0 >,
			             < 0x2d 0x0 >,
			             < 0x2e 0x0 >;    /* in zephyr/dts/arm/gd/gd32f403/gd32f403.dtsi:375 */
			interrupt-names = "brk",
			                  "up",
			                  "trgcom",
			                  "cc";       /* in zephyr/dts/arm/gd/gd32f403/gd32f403.dtsi:376 */
			clocks = < &cctl 0x60d >;     /* in zephyr/dts/arm/gd/gd32f403/gd32f403.dtsi:377 */
			resets = < &rctl 0x30d >;     /* in zephyr/dts/arm/gd/gd32f403/gd32f403.dtsi:378 */
			is-advanced;                  /* in zephyr/dts/arm/gd/gd32f403/gd32f403.dtsi:379 */
			channels = < 0x4 >;           /* in zephyr/dts/arm/gd/gd32f403/gd32f403.dtsi:380 */
			status = "disabled";          /* in zephyr/dts/arm/gd/gd32f403/gd32f403.dtsi:381 */

			/* node '/soc/timer@40013400/pwm' defined in zephyr/dts/arm/gd/gd32f403/gd32f403.dtsi:383 */
			pwm {
				compatible = "gd,gd32-pwm"; /* in zephyr/dts/arm/gd/gd32f403/gd32f403.dtsi:384 */
				status = "disabled";        /* in zephyr/dts/arm/gd/gd32f403/gd32f403.dtsi:385 */
				#pwm-cells = < 0x3 >;       /* in zephyr/dts/arm/gd/gd32f403/gd32f403.dtsi:386 */
			};
		};

		/* node '/soc/timer@40014c00' defined in zephyr/dts/arm/gd/gd32f403/gd32f403.dtsi:390 */
		timer8: timer@40014c00 {
			compatible = "gd,gd32-timer"; /* in zephyr/dts/arm/gd/gd32f403/gd32f403.dtsi:391 */
			reg = < 0x40014c00 0x400 >;   /* in zephyr/dts/arm/gd/gd32f403/gd32f403.dtsi:392 */
			interrupts = < 0x18 0x0 >;    /* in zephyr/dts/arm/gd/gd32f403/gd32f403.dtsi:393 */
			interrupt-names = "global";   /* in zephyr/dts/arm/gd/gd32f403/gd32f403.dtsi:394 */
			clocks = < &cctl 0x613 >;     /* in zephyr/dts/arm/gd/gd32f403/gd32f403.dtsi:395 */
			resets = < &rctl 0x313 >;     /* in zephyr/dts/arm/gd/gd32f403/gd32f403.dtsi:396 */
			channels = < 0x2 >;           /* in zephyr/dts/arm/gd/gd32f403/gd32f403.dtsi:397 */
			status = "disabled";          /* in zephyr/dts/arm/gd/gd32f403/gd32f403.dtsi:398 */

			/* node '/soc/timer@40014c00/pwm' defined in zephyr/dts/arm/gd/gd32f403/gd32f403.dtsi:400 */
			pwm {
				compatible = "gd,gd32-pwm"; /* in zephyr/dts/arm/gd/gd32f403/gd32f403.dtsi:401 */
				status = "disabled";        /* in zephyr/dts/arm/gd/gd32f403/gd32f403.dtsi:402 */
				#pwm-cells = < 0x3 >;       /* in zephyr/dts/arm/gd/gd32f403/gd32f403.dtsi:403 */
			};
		};

		/* node '/soc/timer@40015000' defined in zephyr/dts/arm/gd/gd32f403/gd32f403.dtsi:407 */
		timer9: timer@40015000 {
			compatible = "gd,gd32-timer"; /* in zephyr/dts/arm/gd/gd32f403/gd32f403.dtsi:408 */
			reg = < 0x40015000 0x400 >;   /* in zephyr/dts/arm/gd/gd32f403/gd32f403.dtsi:409 */
			interrupts = < 0x19 0x0 >;    /* in zephyr/dts/arm/gd/gd32f403/gd32f403.dtsi:410 */
			interrupt-names = "global";   /* in zephyr/dts/arm/gd/gd32f403/gd32f403.dtsi:411 */
			clocks = < &cctl 0x614 >;     /* in zephyr/dts/arm/gd/gd32f403/gd32f403.dtsi:412 */
			resets = < &rctl 0x314 >;     /* in zephyr/dts/arm/gd/gd32f403/gd32f403.dtsi:413 */
			channels = < 0x1 >;           /* in zephyr/dts/arm/gd/gd32f403/gd32f403.dtsi:414 */
			status = "disabled";          /* in zephyr/dts/arm/gd/gd32f403/gd32f403.dtsi:415 */

			/* node '/soc/timer@40015000/pwm' defined in zephyr/dts/arm/gd/gd32f403/gd32f403.dtsi:417 */
			pwm {
				compatible = "gd,gd32-pwm"; /* in zephyr/dts/arm/gd/gd32f403/gd32f403.dtsi:418 */
				status = "disabled";        /* in zephyr/dts/arm/gd/gd32f403/gd32f403.dtsi:419 */
				#pwm-cells = < 0x3 >;       /* in zephyr/dts/arm/gd/gd32f403/gd32f403.dtsi:420 */
			};
		};

		/* node '/soc/timer@40015400' defined in zephyr/dts/arm/gd/gd32f403/gd32f403.dtsi:424 */
		timer10: timer@40015400 {
			compatible = "gd,gd32-timer"; /* in zephyr/dts/arm/gd/gd32f403/gd32f403.dtsi:425 */
			reg = < 0x40015400 0x400 >;   /* in zephyr/dts/arm/gd/gd32f403/gd32f403.dtsi:426 */
			interrupts = < 0x1a 0x0 >;    /* in zephyr/dts/arm/gd/gd32f403/gd32f403.dtsi:427 */
			interrupt-names = "global";   /* in zephyr/dts/arm/gd/gd32f403/gd32f403.dtsi:428 */
			clocks = < &cctl 0x615 >;     /* in zephyr/dts/arm/gd/gd32f403/gd32f403.dtsi:429 */
			resets = < &rctl 0x315 >;     /* in zephyr/dts/arm/gd/gd32f403/gd32f403.dtsi:430 */
			channels = < 0x1 >;           /* in zephyr/dts/arm/gd/gd32f403/gd32f403.dtsi:431 */
			status = "disabled";          /* in zephyr/dts/arm/gd/gd32f403/gd32f403.dtsi:432 */

			/* node '/soc/timer@40015400/pwm' defined in zephyr/dts/arm/gd/gd32f403/gd32f403.dtsi:434 */
			pwm {
				compatible = "gd,gd32-pwm"; /* in zephyr/dts/arm/gd/gd32f403/gd32f403.dtsi:435 */
				status = "disabled";        /* in zephyr/dts/arm/gd/gd32f403/gd32f403.dtsi:436 */
				#pwm-cells = < 0x3 >;       /* in zephyr/dts/arm/gd/gd32f403/gd32f403.dtsi:437 */
			};
		};

		/* node '/soc/timer@40001800' defined in zephyr/dts/arm/gd/gd32f403/gd32f403.dtsi:441 */
		timer11: timer@40001800 {
			compatible = "gd,gd32-timer"; /* in zephyr/dts/arm/gd/gd32f403/gd32f403.dtsi:442 */
			reg = < 0x40001800 0x400 >;   /* in zephyr/dts/arm/gd/gd32f403/gd32f403.dtsi:443 */
			interrupts = < 0x2b 0x0 >;    /* in zephyr/dts/arm/gd/gd32f403/gd32f403.dtsi:444 */
			interrupt-names = "global";   /* in zephyr/dts/arm/gd/gd32f403/gd32f403.dtsi:445 */
			clocks = < &cctl 0x706 >;     /* in zephyr/dts/arm/gd/gd32f403/gd32f403.dtsi:446 */
			resets = < &rctl 0x406 >;     /* in zephyr/dts/arm/gd/gd32f403/gd32f403.dtsi:447 */
			channels = < 0x2 >;           /* in zephyr/dts/arm/gd/gd32f403/gd32f403.dtsi:448 */
			status = "disabled";          /* in zephyr/dts/arm/gd/gd32f403/gd32f403.dtsi:449 */

			/* node '/soc/timer@40001800/pwm' defined in zephyr/dts/arm/gd/gd32f403/gd32f403.dtsi:451 */
			pwm {
				compatible = "gd,gd32-pwm"; /* in zephyr/dts/arm/gd/gd32f403/gd32f403.dtsi:452 */
				status = "disabled";        /* in zephyr/dts/arm/gd/gd32f403/gd32f403.dtsi:453 */
				#pwm-cells = < 0x3 >;       /* in zephyr/dts/arm/gd/gd32f403/gd32f403.dtsi:454 */
			};
		};

		/* node '/soc/timer@40001c00' defined in zephyr/dts/arm/gd/gd32f403/gd32f403.dtsi:458 */
		timer12: timer@40001c00 {
			compatible = "gd,gd32-timer"; /* in zephyr/dts/arm/gd/gd32f403/gd32f403.dtsi:459 */
			reg = < 0x40001c00 0x400 >;   /* in zephyr/dts/arm/gd/gd32f403/gd32f403.dtsi:460 */
			interrupts = < 0x2c 0x0 >;    /* in zephyr/dts/arm/gd/gd32f403/gd32f403.dtsi:461 */
			interrupt-names = "global";   /* in zephyr/dts/arm/gd/gd32f403/gd32f403.dtsi:462 */
			clocks = < &cctl 0x707 >;     /* in zephyr/dts/arm/gd/gd32f403/gd32f403.dtsi:463 */
			resets = < &rctl 0x407 >;     /* in zephyr/dts/arm/gd/gd32f403/gd32f403.dtsi:464 */
			channels = < 0x1 >;           /* in zephyr/dts/arm/gd/gd32f403/gd32f403.dtsi:465 */
			status = "disabled";          /* in zephyr/dts/arm/gd/gd32f403/gd32f403.dtsi:466 */

			/* node '/soc/timer@40001c00/pwm' defined in zephyr/dts/arm/gd/gd32f403/gd32f403.dtsi:468 */
			pwm {
				compatible = "gd,gd32-pwm"; /* in zephyr/dts/arm/gd/gd32f403/gd32f403.dtsi:469 */
				status = "disabled";        /* in zephyr/dts/arm/gd/gd32f403/gd32f403.dtsi:470 */
				#pwm-cells = < 0x3 >;       /* in zephyr/dts/arm/gd/gd32f403/gd32f403.dtsi:471 */
			};
		};

		/* node '/soc/timer@40002000' defined in zephyr/dts/arm/gd/gd32f403/gd32f403.dtsi:475 */
		timer13: timer@40002000 {
			compatible = "gd,gd32-timer"; /* in zephyr/dts/arm/gd/gd32f403/gd32f403.dtsi:476 */
			reg = < 0x40002000 0x400 >;   /* in zephyr/dts/arm/gd/gd32f403/gd32f403.dtsi:477 */
			interrupts = < 0x2d 0x0 >;    /* in zephyr/dts/arm/gd/gd32f403/gd32f403.dtsi:478 */
			interrupt-names = "global";   /* in zephyr/dts/arm/gd/gd32f403/gd32f403.dtsi:479 */
			clocks = < &cctl 0x708 >;     /* in zephyr/dts/arm/gd/gd32f403/gd32f403.dtsi:480 */
			resets = < &rctl 0x408 >;     /* in zephyr/dts/arm/gd/gd32f403/gd32f403.dtsi:481 */
			channels = < 0x1 >;           /* in zephyr/dts/arm/gd/gd32f403/gd32f403.dtsi:482 */
			status = "disabled";          /* in zephyr/dts/arm/gd/gd32f403/gd32f403.dtsi:483 */

			/* node '/soc/timer@40002000/pwm' defined in zephyr/dts/arm/gd/gd32f403/gd32f403.dtsi:485 */
			pwm {
				compatible = "gd,gd32-pwm"; /* in zephyr/dts/arm/gd/gd32f403/gd32f403.dtsi:486 */
				status = "disabled";        /* in zephyr/dts/arm/gd/gd32f403/gd32f403.dtsi:487 */
				#pwm-cells = < 0x3 >;       /* in zephyr/dts/arm/gd/gd32f403/gd32f403.dtsi:488 */
			};
		};

		/* node '/soc/dma@40020000' defined in zephyr/dts/arm/gd/gd32f403/gd32f403.dtsi:492 */
		dma0: dma@40020000 {
			compatible = "gd,gd32-dma"; /* in zephyr/dts/arm/gd/gd32f403/gd32f403.dtsi:493 */
			reg = < 0x40020000 0x400 >; /* in zephyr/dts/arm/gd/gd32f403/gd32f403.dtsi:494 */
			interrupts = < 0xb 0x0 >,
			             < 0xc 0x0 >,
			             < 0xd 0x0 >,
			             < 0xe 0x0 >,
			             < 0xf 0x0 >,
			             < 0x10 0x0 >,
			             < 0x11 0x0 >;  /* in zephyr/dts/arm/gd/gd32f403/gd32f403.dtsi:495 */
			clocks = < &cctl 0x500 >;   /* in zephyr/dts/arm/gd/gd32f403/gd32f403.dtsi:497 */
			dma-channels = < 0x7 >;     /* in zephyr/dts/arm/gd/gd32f403/gd32f403.dtsi:498 */
			gd,mem2mem;                 /* in zephyr/dts/arm/gd/gd32f403/gd32f403.dtsi:499 */
			#dma-cells = < 0x2 >;       /* in zephyr/dts/arm/gd/gd32f403/gd32f403.dtsi:500 */
			status = "disabled";        /* in zephyr/dts/arm/gd/gd32f403/gd32f403.dtsi:501 */
		};

		/* node '/soc/dma@40020400' defined in zephyr/dts/arm/gd/gd32f403/gd32f403.dtsi:504 */
		dma1: dma@40020400 {
			compatible = "gd,gd32-dma"; /* in zephyr/dts/arm/gd/gd32f403/gd32f403.dtsi:505 */
			reg = < 0x40020400 0x400 >; /* in zephyr/dts/arm/gd/gd32f403/gd32f403.dtsi:506 */
			interrupts = < 0x38 0x0 >,
			             < 0x39 0x0 >,
			             < 0x3a 0x0 >,
			             < 0x3b 0x0 >,
			             < 0x3c 0x0 >;  /* in zephyr/dts/arm/gd/gd32f403/gd32f403.dtsi:507 */
			clocks = < &cctl 0x501 >;   /* in zephyr/dts/arm/gd/gd32f403/gd32f403.dtsi:509 */
			dma-channels = < 0x5 >;     /* in zephyr/dts/arm/gd/gd32f403/gd32f403.dtsi:510 */
			gd,mem2mem;                 /* in zephyr/dts/arm/gd/gd32f403/gd32f403.dtsi:511 */
			#dma-cells = < 0x2 >;       /* in zephyr/dts/arm/gd/gd32f403/gd32f403.dtsi:512 */
			status = "disabled";        /* in zephyr/dts/arm/gd/gd32f403/gd32f403.dtsi:513 */
		};
	};

	/* node '/cpus' defined in zephyr/dts/arm/gd/gd32f403/gd32f403.dtsi:17 */
	cpus {
		#address-cells = < 0x1 >; /* in zephyr/dts/arm/gd/gd32f403/gd32f403.dtsi:18 */
		#size-cells = < 0x0 >;    /* in zephyr/dts/arm/gd/gd32f403/gd32f403.dtsi:19 */

		/* node '/cpus/cpu@0' defined in zephyr/dts/arm/gd/gd32f403/gd32f403.dtsi:21 */
		cpu0: cpu@0 {
			compatible = "arm,cortex-m4f";   /* in zephyr/dts/arm/gd/gd32f403/gd32f403.dtsi:22 */
			clock-frequency = < 0xa037a00 >; /* in zephyr/dts/arm/gd/gd32f403/gd32f403.dtsi:23 */
			reg = < 0x0 >;                   /* in zephyr/dts/arm/gd/gd32f403/gd32f403.dtsi:24 */
			#address-cells = < 0x1 >;        /* in zephyr/dts/arm/gd/gd32f403/gd32f403.dtsi:25 */
			#size-cells = < 0x1 >;           /* in zephyr/dts/arm/gd/gd32f403/gd32f403.dtsi:26 */

			/* node '/cpus/cpu@0/mpu@e000ed90' defined in zephyr/dts/arm/gd/gd32f403/gd32f403.dtsi:28 */
			mpu: mpu@e000ed90 {
				compatible = "arm,armv7m-mpu"; /* in zephyr/dts/arm/gd/gd32f403/gd32f403.dtsi:29 */
				reg = < 0xe000ed90 0x40 >;     /* in zephyr/dts/arm/gd/gd32f403/gd32f403.dtsi:30 */
			};
		};
	};

	/* node '/leds' defined in zephyr/boards/gd/gd32f403z_eval/gd32f403z_eval.dts:24 */
	leds {
		compatible = "gpio-leds"; /* in zephyr/boards/gd/gd32f403z_eval/gd32f403z_eval.dts:25 */

		/* node '/leds/led2' defined in zephyr/boards/gd/gd32f403z_eval/gd32f403z_eval.dts:27 */
		led2: led2 {
			gpios = < &gpiof 0x0 0x0 >; /* in zephyr/boards/gd/gd32f403z_eval/gd32f403z_eval.dts:28 */
			label = "LED2";             /* in zephyr/boards/gd/gd32f403z_eval/gd32f403z_eval.dts:29 */
		};

		/* node '/leds/led3' defined in zephyr/boards/gd/gd32f403z_eval/gd32f403z_eval.dts:32 */
		led3: led3 {
			gpios = < &gpiof 0x1 0x0 >; /* in zephyr/boards/gd/gd32f403z_eval/gd32f403z_eval.dts:33 */
			label = "LED3";             /* in zephyr/boards/gd/gd32f403z_eval/gd32f403z_eval.dts:34 */
		};

		/* node '/leds/led4' defined in zephyr/boards/gd/gd32f403z_eval/gd32f403z_eval.dts:37 */
		led4: led4 {
			gpios = < &gpiof 0x2 0x0 >; /* in zephyr/boards/gd/gd32f403z_eval/gd32f403z_eval.dts:38 */
			label = "LED4";             /* in zephyr/boards/gd/gd32f403z_eval/gd32f403z_eval.dts:39 */
		};

		/* node '/leds/led5' defined in zephyr/boards/gd/gd32f403z_eval/gd32f403z_eval.dts:42 */
		led5: led5 {
			gpios = < &gpiof 0x3 0x0 >; /* in zephyr/boards/gd/gd32f403z_eval/gd32f403z_eval.dts:43 */
			label = "LED5";             /* in zephyr/boards/gd/gd32f403z_eval/gd32f403z_eval.dts:44 */
		};
	};

	/* node '/gpio_keys' defined in zephyr/boards/gd/gd32f403z_eval/gd32f403z_eval.dts:48 */
	gpio_keys {
		compatible = "gpio-keys"; /* in zephyr/boards/gd/gd32f403z_eval/gd32f403z_eval.dts:49 */

		/* node '/gpio_keys/wakeup_key' defined in zephyr/boards/gd/gd32f403z_eval/gd32f403z_eval.dts:51 */
		wakeup_key: wakeup_key {
			label = "WAKEUP_KEY";       /* in zephyr/boards/gd/gd32f403z_eval/gd32f403z_eval.dts:52 */
			gpios = < &gpioa 0x0 0x1 >; /* in zephyr/boards/gd/gd32f403z_eval/gd32f403z_eval.dts:53 */
			zephyr,code = < 0x8f >;     /* in zephyr/boards/gd/gd32f403z_eval/gd32f403z_eval.dts:54 */
		};

		/* node '/gpio_keys/tamper_key' defined in zephyr/boards/gd/gd32f403z_eval/gd32f403z_eval.dts:57 */
		tamper_key: tamper_key {
			label = "TAMPER_KEY";       /* in zephyr/boards/gd/gd32f403z_eval/gd32f403z_eval.dts:58 */
			gpios = < &gpioc 0xd 0x1 >; /* in zephyr/boards/gd/gd32f403z_eval/gd32f403z_eval.dts:59 */
			zephyr,code = < 0xb >;      /* in zephyr/boards/gd/gd32f403z_eval/gd32f403z_eval.dts:60 */
		};

		/* node '/gpio_keys/user_key1' defined in zephyr/boards/gd/gd32f403z_eval/gd32f403z_eval.dts:63 */
		user_key1: user_key1 {
			label = "USER_KEY1";        /* in zephyr/boards/gd/gd32f403z_eval/gd32f403z_eval.dts:64 */
			gpios = < &gpiof 0x5 0x1 >; /* in zephyr/boards/gd/gd32f403z_eval/gd32f403z_eval.dts:65 */
			zephyr,code = < 0x2 >;      /* in zephyr/boards/gd/gd32f403z_eval/gd32f403z_eval.dts:66 */
		};

		/* node '/gpio_keys/user_key2' defined in zephyr/boards/gd/gd32f403z_eval/gd32f403z_eval.dts:69 */
		user_key2: user_key2 {
			label = "USER_KEY2";        /* in zephyr/boards/gd/gd32f403z_eval/gd32f403z_eval.dts:70 */
			gpios = < &gpiof 0x4 0x1 >; /* in zephyr/boards/gd/gd32f403z_eval/gd32f403z_eval.dts:71 */
			zephyr,code = < 0x3 >;      /* in zephyr/boards/gd/gd32f403z_eval/gd32f403z_eval.dts:72 */
		};
	};

	/* node '/pwmleds' defined in zephyr/boards/gd/gd32f403z_eval/gd32f403z_eval.dts:76 */
	pwmleds {
		compatible = "pwm-leds"; /* in zephyr/boards/gd/gd32f403z_eval/gd32f403z_eval.dts:77 */

		/* node '/pwmleds/pwm_led' defined in zephyr/boards/gd/gd32f403z_eval/gd32f403z_eval.dts:80 */
		pwm_led: pwm_led {
			pwms = < &pwm0 0x0 0x1312d00 0x0 >; /* in zephyr/boards/gd/gd32f403z_eval/gd32f403z_eval.dts:81 */
		};
	};
};
